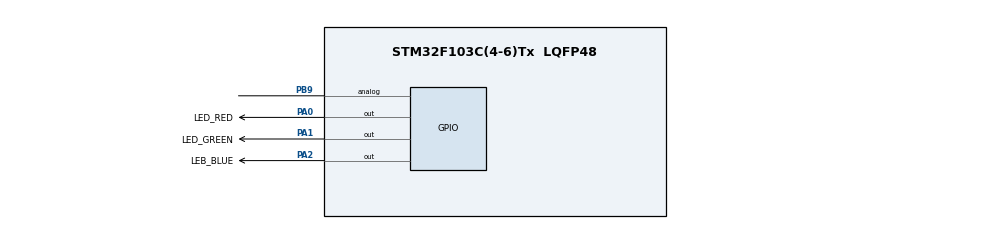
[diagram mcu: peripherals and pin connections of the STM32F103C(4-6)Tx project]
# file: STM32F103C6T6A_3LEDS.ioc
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Mcu.Family=STM32F1
Mcu.Name=STM32F103C(4-6)Tx
Mcu.Package=LQFP48
NVIC.PriorityGroup=NVIC_PRIORITYGROUP_4
PA0-WKUP.GPIO_Label=LED_RED
PA0-WKUP.GPIO_Speed=GPIO_SPEED_FREQ_HIGH
PA0-WKUP.PinState=GPIO_PIN_SET
PA0-WKUP.Signal=GPIO_Output
PA1.GPIO_Label=LED_GREEN
PA1.GPIO_Speed=GPIO_SPEED_FREQ_HIGH
PA1.PinState=GPIO_PIN_SET
PA1.Signal=GPIO_Output
PA13.Mode=Serial_Wire
PA13.Signal=SYS_JTMS-SWDIO
PA14.Mode=Serial_Wire
PA14.Signal=SYS_JTCK-SWCLK
PA2.GPIO_Label=LEB_BLUE
PA2.GPIO_Speed=GPIO_SPEED_FREQ_HIGH
PA2.PinState=GPIO_PIN_SET
PA2.Signal=GPIO_Output
PB9.Signal=GPIO_Analog
PC14-OSC32_IN.Mode=LSE-External-Oscillator
PC14-OSC32_IN.Signal=RCC_OSC32_IN
PC15-OSC32_OUT.Mode=LSE-External-Oscillator
PC15-OSC32_OUT.Signal=RCC_OSC32_OUT
PD0-OSC_IN.Mode=HSE-External-Oscillator
PD0-OSC_IN.Signal=RCC_OSC_IN
PD1-OSC_OUT.Mode=HSE-External-Oscillator
PD1-OSC_OUT.Signal=RCC_OSC_OUT
ProjectManager.HeapSize=0x200
ProjectManager.StackSize=0x400
ProjectManager.TargetToolchain=STM32CubeIDE
RCC.APB1Freq_Value=8000000
RCC.APB2Freq_Value=8000000
board=custom

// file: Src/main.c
/* USER CODE BEGIN Header */
/**
  ******************************************************************************
  * @file           : main.c
  * @brief          : Main program body
  ******************************************************************************
  * @attention
  *
  * Copyright (c) 2026 STMicroelectronics.
  * All rights reserved.
  *
  * This software is licensed under terms that can be found in the LICENSE file
  * in the root directory of this software component.
  * If no LICENSE file comes with this software, it is provided AS-IS.
  *
  ******************************************************************************
  */
/* USER CODE END Header */
#include "main.h"

void SystemClock_Config(void);
static void MX_GPIO_Init(void);

int main(void)
{

  /* MCU Configuration--------------------------------------------------------*/

  /* Reset of all peripherals, Initializes the Flash interface and the Systick. */
  HAL_Init();

  /* Configure the system clock */
  SystemClock_Config();

  /* Initialize all configured peripherals */
  MX_GPIO_Init();

  /* Infinite loop */
  while (1)
  {

    /* USER CODE BEGIN 3 */
	  HAL_GPIO_TogglePin(GPIOA, LED_RED_Pin|LED_GREEN_Pin|LEB_BLUE_Pin);
	  HAL_Delay(1000);
  }
  /* USER CODE END 3 */
}

void SystemClock_Config(void)
{
  RCC_OscInitTypeDef RCC_OscInitStruct = {0};
  RCC_ClkInitTypeDef RCC_ClkInitStruct = {0};

  /** Initializes the RCC Oscillators according to the specified parameters
  * in the RCC_OscInitTypeDef structure.
  */
  RCC_OscInitStruct.OscillatorType = RCC_OSCILLATORTYPE_HSI;
  RCC_OscInitStruct.HSIState = RCC_HSI_ON;
  RCC_OscInitStruct.HSICalibrationValue = RCC_HSICALIBRATION_DEFAULT;
  RCC_OscInitStruct.PLL.PLLState = RCC_PLL_NONE;
  if (HAL_RCC_OscConfig(&RCC_OscInitStruct) != HAL_OK)
  {
    Error_Handler();
  }

  /** Initializes the CPU, AHB and APB buses clocks
  */
  RCC_ClkInitStruct.ClockType = RCC_CLOCKTYPE_HCLK|RCC_CLOCKTYPE_SYSCLK
                              |RCC_CLOCKTYPE_PCLK1|RCC_CLOCKTYPE_PCLK2;
  RCC_ClkInitStruct.SYSCLKSource = RCC_SYSCLKSOURCE_HSI;
  RCC_ClkInitStruct.AHBCLKDivider = RCC_SYSCLK_DIV1;
  RCC_ClkInitStruct.APB1CLKDivider = RCC_HCLK_DIV1;
  RCC_ClkInitStruct.APB2CLKDivider = RCC_HCLK_DIV1;

  if (HAL_RCC_ClockConfig(&RCC_ClkInitStruct, FLASH_LATENCY_0) != HAL_OK)
  {
    Error_Handler();
  }
}

static void MX_GPIO_Init(void)
{
  GPIO_InitTypeDef GPIO_InitStruct = {0};

  /* GPIO Ports Clock Enable */
  __HAL_RCC_GPIOC_CLK_ENABLE();
  __HAL_RCC_GPIOD_CLK_ENABLE();
  __HAL_RCC_GPIOA_CLK_ENABLE();

  /*Configure GPIO pin Output Level */
  HAL_GPIO_WritePin(GPIOA, LED_RED_Pin|LED_GREEN_Pin|LEB_BLUE_Pin, GPIO_PIN_SET);

  /*Configure GPIO pins : LED_RED_Pin LED_GREEN_Pin LEB_BLUE_Pin */
  GPIO_InitStruct.Pin = LED_RED_Pin|LED_GREEN_Pin|LEB_BLUE_Pin;
  GPIO_InitStruct.Mode = GPIO_MODE_OUTPUT_PP;
  GPIO_InitStruct.Pull = GPIO_NOPULL;
  GPIO_InitStruct.Speed = GPIO_SPEED_FREQ_HIGH;
  HAL_GPIO_Init(GPIOA, &GPIO_InitStruct);

}

void Error_Handler(void)
{
  __disable_irq();
  while (1)
  {
  }
}
